# M0A21 register map
File version: 1.0
Registers are 32-bit, read-write, reset 0x0 unless marked. A register's access mark holds for its fields unless they carry their own. Offsets are from the block's base; [hi:lo] are bit positions; 'fields as' and 'values as' point back to an identical list.

## TMR01 — TIMER Register Map
Base 0x40050000
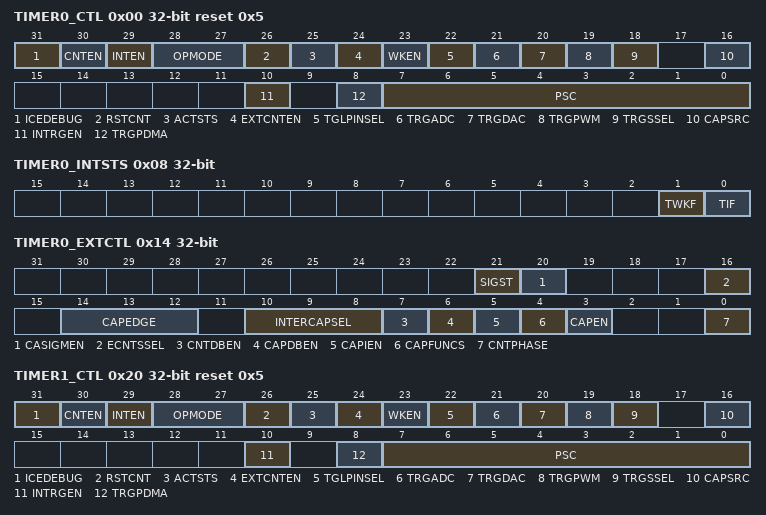
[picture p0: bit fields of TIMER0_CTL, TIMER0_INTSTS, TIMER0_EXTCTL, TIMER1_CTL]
0x00 TIMER0_CTL reset 0x5 — Timer0 Control Register
  [31] ICEDEBUG — ICE Debug Mode Acknowledge Disable Bit (Write Protect). TIMER counter will keep going no matter CPU is held by ICE or not. Note: This bit is write protected. Refer to the SYS_REGLCTL register.
    0=ICE debug mode acknowledgement effects TIMER counting; 1=ICE debug mode acknowledgement Disabled
  [30] CNTEN — Timer Counting Enable Bit. Note 3: Setting enable/disable this bit needs 2 * TMR_CLK period to become active. User can read ACTSTS (TIMERx_CTL[25]) to check enable/disable command is completed or not.
    0=Stops/Suspends counting; 1=Starts counting
  [29] INTEN — Timer Interrupt Enable Bit. Note: If this bit is enabled, when the timer time-out interrupt flag TIF is set to 1, the timer interrupt signal is generated and inform to CPU.
    0=Timer time-out interrupt Disabled; 1=Timer time-out interrupt Enabled
  [28:27] OPMODE — Timer Counting Mode Select
    0=The timer controller is operated in One-shot mode; 1=The timer controller is operated in Periodic mode; 2=The timer controller is operated in Toggle-output mode; 3=The timer controller is operated in Continuous Counting mode
  [26] RSTCNT — Timer Counter Reset Bit. Setting this bit will reset the 24-bit up counter value CNT (TIMERx_CNT[23:0]) and also force CNTEN (TIMERx_CTL[30]) to 0 if ACTSTS (TIMERx_CTL[25]) is 1. Note: This bit will be auto cleared.
    0=No effect; 1=Reset internal 8-bit prescale counter, 24-bit up counter value and CNTEN bit
  [25] ACTSTS ro — Timer Active Status Bit (Read Only). This bit indicates the 24-bit up counter status. Note: This bit may be active when CNT 0 transition to CNT 1.
    0=24-bit up counter is not active; 1=24-bit up counter is active
  [24] EXTCNTEN — Event Counter Mode Enable Bit. This bit is for external counting pin function enabled. Note 2: When TMR0/TMR2 INTRGEN is set to 1, this bit is forced to 1. When INTRGEN is 1 and TMR1/TMR3 CAPIF (TIMERx_EINTSTS[0]) is 1, this bit is forced to 0.
    0=Event counter mode Disabled; 1=Event counter mode Enabled
  [23] WKEN — Wake-up Function Enable Bit. If this bit is set to 1, while timer interrupt flag TIF (TIMERx_INTSTS[0]) is 1 and INTEN (TIMERx_CTL[29]) is enabled, the timer interrupt signal will generate a wake-up trigger event to CPU.
    0=Wake-up function Disabled if timer interrupt signal generated; 1=Wake-up function Enabled if timer interrupt signal generated
  [22] TGLPINSEL — Toggle-output Pin Select
    0=Toggle mode output to Tx (Timer Event Counter Pin); 1=Toggle mode output to Tx_EXT (Timer External Capture Pin)
  [21] TRGADC — Trigger ADC Enable Bit. If this bit is set to 1, timer time-out interrupt or capture interrupt can trigger ADC.
    0=Timer interrupt trigger ADC Disabled; 1=Timer interrupt trigger ADC Enabled
  [20] TRGDAC — Trigger DAC Enable Bit. If this bit is set to 1, timer time-out interrupt or capture interrupt can trigger DAC.
    0=Timer interrupt trigger DAC Disabled; 1=Timer interrupt trigger DAC Enabled
  [19] TRGPWM — Trigger PWM Enable Bit. If this bit is set to 1, timer time-out interrupt or capture interrupt can trigger PWM.
    0=Timer interrupt trigger PWM Disabled; 1=Timer interrupt trigger PWM Enabled
  [18] TRGSSEL — Trigger Source Select Bit. This bit is used to select trigger source is from Timer time-out interrupt signal or capture interrupt signal.
    0=Timer time-out interrupt signal is used to trigger PWM, DAC, ADC and PDMA; 1=Capture interrupt signal is used to trigger PWM, DAC, ADC and PDMA
  [16] CAPSRC — Capture Pin Source Selection
    0=Capture Function source is from TMx_EXT (x= 0~3) pin; 1=Capture Function source is from internal ACMP output signal or LIRC. User can set INTERCAPSEL (TIMERx_EXTCTL[10:8]) to decide which internal ACMP output signal or LIRC is timer capture source
  [10] INTRGEN — Inter-timer Trigger Mode Enable Bit. Setting this bit will enable the inter-timer trigger capture function. The Timer0/2 will be in event counter mode and counting with external clock source or event.Also, Timer1/3 will be in trigger-counting mode of capture function. Note: For Timer1/3, this bit is ignored and the read back value is always 0.
    0=Inter-Timer Trigger mode Disabled; 1=Inter-Timer Trigger mode Enabled
  [8] TRGPDMA — Trigger PDMA Enable Bit. If this bit is set to 1, timer time-out interrupt or capture interrupt can trigger PDMA.
    0=Timer interrupt trigger PDMA Disabled; 1=Timer interrupt trigger PDMA Enabled
  [7:0] PSC — Prescale Counter. Note: Updating prescale counter value will reset internal 8-bit prescale counter and 24-bit up counter value.
0x04 TIMER0_CMP — Timer0 Comparator Register
  [23:0] CMPDAT — Timer Comparator Value. CMPDAT is a 24-bit compared value register. When the internal 24-bit up counter value is equal to CMPDAT value, the TIF (TIMERx_INTSTS[0] Timer Interrupt Flag) will set to 1. Note 1: Never write 0x0 or 0x1 in CMPDAT field, or the core will run into unknown state. Note 2: When timer is operating at continuous counting mode, the 24-bit up counter will keep counting continuously even if user writes a new value into CMPDAT field. But if timer is operating at other modes, the 24-bit up counter will restart counting from 0 and using the newest CMPDAT value to be the timer compared value while user writes a new value into CMPDAT field.
0x08 TIMER0_INTSTS — Timer0 Interrupt Status Register
  [1] TWKF — Timer Wake-up Flag. This bit indicates the interrupt wake-up flag status of timer. Note: This bit is cleared by writing 1 to it.
    0=Timer does not cause CPU wake-up; 1=CPU wake-up from Idle or Power-down mode if timer time-out interrupt signal generated
  [0] TIF — Timer Interrupt Flag. This bit indicates the interrupt flag status of Timer while 24-bit timer up counter CNT (TIMERx_CNT[23:0]) value reaches CMPDAT (TIMERx_CMP[23:0]) value. Note: This bit is cleared by writing 1 to it.
    0=No effect; 1=CNT value matches the CMPDAT value
0x0C TIMER0_CNT ro — Timer0 Data Register
  [23:0] CNT — Timer Data Register. Read this register to get CNT value. For example: If EXTCNTEN (TIMERx_CTL[24]) is 0, user can read CNT value for getting current 24-bit counter value. If EXTCNTEN (TIMERx_CTL[24]) is 1, user can read CNT value for getting current 24-bit event input counter value.
0x10 TIMER0_CAP ro — Timer0 Capture Data Register
  [23:0] CAPDAT — Timer Capture Data Register. When CAPEN (TIMERx_EXTCTL[3]) bit is set, and a transition on TMx_EXT pin matched the CAPEDGE (TIMERx_EXTCTL[14:12]) setting, CAPIF (TIMERx_EINTSTS[0]) will set to 1 and the current timer counter value CNT (TIMERx_CNT[23:0]) will be auto-loaded into this CAPDAT field.
0x14 TIMER0_EXTCTL — Timer0 External Control Register
  [21] SIGST — Single Measure Start Bit. User can write 1'b1 to this bit to let timer start measure TMx_EXT pin. When capture measure event finishes this bit will auto clear by hardware.
  [20] CASIGMEN — Capture Single Measure Mode Enable Bit. Note: these bits only available when CAPEN (TIMERx_EXTCTL[3]) is 1.
    0=Single Measure Mode Disabled; 1=Single Measure Mode Enabled
  [16] ECNTSSEL — Event Counter Source Selection to Trigger Event Counter Function
    0=Event Counter input source is from TMx (x= 0~3) pin
  [14:12] CAPEDGE — Timer External Capture Pin Edge Detect. When first capture event is generated, the CNT (TIMERx_CNT[23:0]) will be reset to 0 and first CAPDAT (TIMERx_CAP[23:0]) will be set to 0. Disable Single Pulse Mode :
    0=Capture event occurred when detect falling edge transfer on TMx_EXT (x= 0~3) pin. Measure falling edge ( falling edge transfer on TMx_EXT (x= 0~3) pin; 1=Capture event occurred when detect rising edge transfer on TMx_EXT (x= 0~3) pin. Measure rising edge ( rising edge transfer on TMx_EXT (x= 0~3) pin; 2=Capture event occurred when detect both falling and rising edge transfer on TMx_EXT (x= 0~3) pin, and first capture event occurred at falling edge transfer; 3=Capture event occurred when detect both rising and falling edge transfer on TMx_EXT (x= 0~3) pin, and first capture event occurred at rising edge transfer; 6=First capture event occurred at falling edge, follows capture events are at rising edge transfer on TMx_EXT (x= 0~3) pin. Measure falling edge ( rising edge transfer on TMx_EXT (x= 0~3) pin; 7=First capture event occurred at rising edge, follows capture events are at falling edge transfer on TMx_EXT (x= 0~3) pin. Measure rising edge ( falling edge transfer on TMx_EXT (x= 0~3) pin
  [10:8] INTERCAPSEL — Internal Capture Source Selection to Trigger Capture Function. Note: these bits only available when CAPSRC (TIMERx_CTL[16]) is 1.
    0=Capture Function source is from internal ACMP0 output signal; 1=Capture Function source is from internal ACMP1 output signal; 5=Capture Function source is from LIRC
  [7] CNTDBEN — Timer Counter Pin De-bounce Enable Bit. Note: If this bit is enabled, the edge detection of TMx pin is detected with de-bounce circuit.
    0=TMx (x= 0~3) pin de-bounce Disabled; 1=TMx (x= 0~3) pin de-bounce Enabled
  [6] CAPDBEN — Timer External Capture Pin De-bounce Enable Bit. Note: If this bit is enabled, the edge detection of TMx_EXT pin or ACMP output is detected with de-bounce circuit.
    0=TMx_EXT (x= 0~3) pin de-bounce or ACMP output de-bounce Disabled; 1=TMx_EXT (x= 0~3) pin de-bounce or ACMP output de-bounce Enabled
  [5] CAPIEN — Timer External Capture Interrupt Enable Bit
    0=TMx_EXT (x= 0~3) pin, LIRC, or ACMP detection Interrupt Disabled; 1=TMx_EXT (x= 0~3) pin, LIRC, or ACMP detection Interrupt Enabled
  [4] CAPFUNCS — Capture Function Selection
    0=External Capture Mode Enabled; 1=External Reset Mode Enabled
  [3] CAPEN — Timer Capture Enable Bit. This bit enables the capture input function. Note: TMR1/TMR3 CAPEN will be forced to 1 when TMR0/TMR2 INTRGEN is enabled.
    0=Capture source Disabled; 1=Capture source Enabled
  [0] CNTPHASE — Timer External Count Phase
    0=A falling edge of external counting pin will be counted; 1=A rising edge of external counting pin will be counted
0x18 TIMER0_EINTSTS — Timer0 External Interrupt Status Register
  [0] CAPIF — Timer External Capture Interrupt Flag. This bit indicates the timer external capture interrupt flag status. Note 3: There is a new incoming capture event detected before CPU clearing the CAPIF status. If the above condition occurred, the Timer will keep register TIMERx_CAP unchanged and drop the new capture value.
    0=TMx_EXT (x= 0~3) pin interrupt did not occur; 1=TMx_EXT (x= 0~3) pin interrupt occurred
0x20 TIMER1_CTL reset 0x5 — Timer1 Control Register
  fields as TIMER0_CTL
0x24 TIMER1_CMP — Timer1 Comparator Register
  fields as TIMER0_CMP
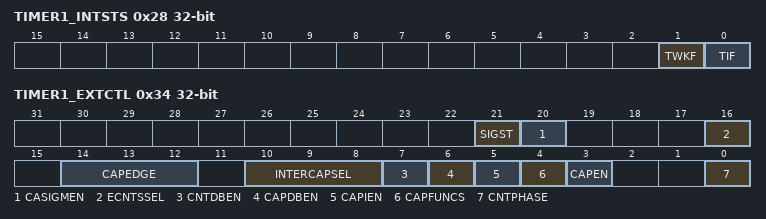
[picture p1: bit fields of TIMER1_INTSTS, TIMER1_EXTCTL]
0x28 TIMER1_INTSTS — Timer1 Interrupt Status Register
  fields as TIMER0_INTSTS
0x2C TIMER1_CNT ro — Timer1 Data Register
  fields as TIMER0_CNT
0x30 TIMER1_CAP ro — Timer1 Capture Data Register
  fields as TIMER0_CAP
0x34 TIMER1_EXTCTL — Timer1 External Control Register
  fields as TIMER0_EXTCTL
0x38 TIMER1_EINTSTS — Timer1 External Interrupt Status Register
  fields as TIMER0_EINTSTS
